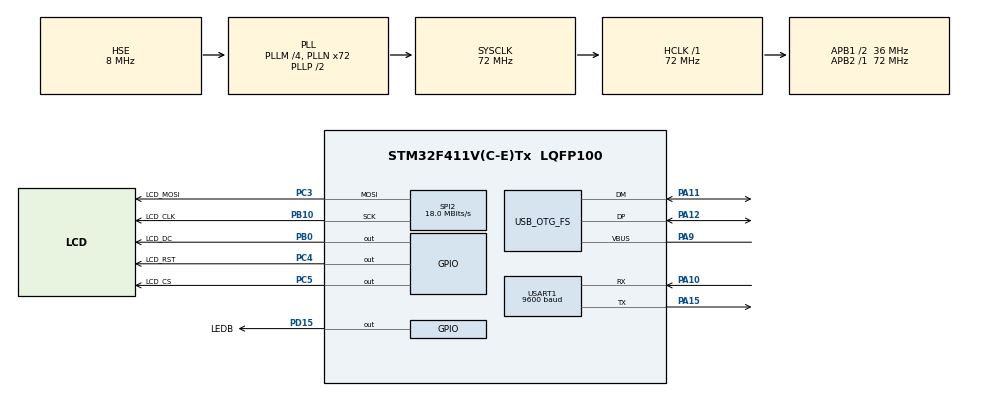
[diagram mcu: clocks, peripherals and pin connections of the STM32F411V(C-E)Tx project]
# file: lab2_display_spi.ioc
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Dma.Request0=USART1_RX
Dma.Request1=SPI2_TX
Dma.SPI2_TX.1.Direction=DMA_MEMORY_TO_PERIPH
Dma.SPI2_TX.1.FIFOMode=DMA_FIFOMODE_DISABLE
Dma.SPI2_TX.1.Instance=DMA1_Stream4
Dma.SPI2_TX.1.MemDataAlignment=DMA_MDATAALIGN_BYTE
Dma.SPI2_TX.1.MemInc=DMA_MINC_ENABLE
Dma.SPI2_TX.1.Mode=DMA_NORMAL
Dma.SPI2_TX.1.PeriphDataAlignment=DMA_PDATAALIGN_BYTE
Dma.SPI2_TX.1.PeriphInc=DMA_PINC_DISABLE
Dma.SPI2_TX.1.Priority=DMA_PRIORITY_LOW
Dma.USART1_RX.0.Direction=DMA_PERIPH_TO_MEMORY
Dma.USART1_RX.0.FIFOMode=DMA_FIFOMODE_DISABLE
Dma.USART1_RX.0.Instance=DMA2_Stream5
Dma.USART1_RX.0.MemDataAlignment=DMA_MDATAALIGN_BYTE
Dma.USART1_RX.0.MemInc=DMA_MINC_ENABLE
Dma.USART1_RX.0.Mode=DMA_CIRCULAR
Dma.USART1_RX.0.PeriphDataAlignment=DMA_PDATAALIGN_BYTE
Dma.USART1_RX.0.PeriphInc=DMA_PINC_DISABLE
Dma.USART1_RX.0.Priority=DMA_PRIORITY_LOW
Mcu.Family=STM32F4
Mcu.Name=STM32F411V(C-E)Tx
Mcu.Package=LQFP100
NVIC.DMA1_Stream4_IRQn=true\:0\:0\:false\:false\:true\:false\:true\:true
NVIC.DMA2_Stream5_IRQn=true\:0\:0\:false\:false\:true\:false\:true\:true
NVIC.OTG_FS_IRQn=true\:0\:0\:false\:false\:true\:false\:true\:true
NVIC.PriorityGroup=NVIC_PRIORITYGROUP_0
PA10.Mode=Asynchronous
PA10.Signal=USART1_RX
PA11.Mode=Device_Only
PA11.Signal=USB_OTG_FS_DM
PA12.Mode=Device_Only
PA12.Signal=USB_OTG_FS_DP
PA13.Mode=Serial_Wire
PA13.Signal=SYS_JTMS-SWDIO
PA14.Mode=Serial_Wire
PA14.Signal=SYS_JTCK-SWCLK
PA15.Mode=Asynchronous
PA15.Signal=USART1_TX
PA9.Mode=Activate_VBUS
PA9.Signal=USB_OTG_FS_VBUS
PB0.GPIO_Label=LCD_DC
PB0.GPIO_PuPd=GPIO_PULLUP
PB0.Signal=GPIO_Output
PB10.GPIO_Label=LCD_CLK
PB10.Mode=TX_Only_Simplex_Unidirect_Master
PB10.Signal=SPI2_SCK
PC14-OSC32_IN.Mode=LSE-External-Oscillator
PC14-OSC32_IN.Signal=RCC_OSC32_IN
PC15-OSC32_OUT.Mode=LSE-External-Oscillator
PC15-OSC32_OUT.Signal=RCC_OSC32_OUT
PC3.GPIO_Label=LCD_MOSI
PC3.Mode=TX_Only_Simplex_Unidirect_Master
PC3.Signal=SPI2_MOSI
PC4.GPIO_Label=LCD_RST
PC4.GPIO_PuPd=GPIO_PULLUP
PC4.Signal=GPIO_Output
PC5.GPIO_Label=LCD_CS
PC5.GPIO_PuPd=GPIO_PULLUP
PC5.Signal=GPIO_Output
PD15.GPIO_Label=LEDB
PD15.GPIO_PuPd=GPIO_PULLUP
PD15.Signal=GPIO_Output
PH0\ -\ OSC_IN.Mode=HSE-External-Oscillator
PH0\ -\ OSC_IN.Signal=RCC_OSC_IN
PH1\ -\ OSC_OUT.Mode=HSE-External-Oscillator
PH1\ -\ OSC_OUT.Signal=RCC_OSC_OUT
ProjectManager.HeapSize=0x0
ProjectManager.StackSize=0x400
ProjectManager.TargetToolchain=CMake
RCC.48MHZClocksFreq_Value=48000000
RCC.AHBFreq_Value=72000000
RCC.APB1CLKDivider=RCC_HCLK_DIV2
RCC.APB1Freq_Value=36000000
RCC.APB1TimFreq_Value=72000000
RCC.APB2Freq_Value=72000000
RCC.APB2TimFreq_Value=72000000
RCC.CortexFreq_Value=72000000
RCC.HCLKFreq_Value=72000000
RCC.HSE_VALUE=8000000
RCC.HSI_VALUE=16000000
RCC.PLLI2SM=5
RCC.PLLI2SN=200
RCC.PLLM=4
RCC.PLLN=72
RCC.PLLQ=3
RCC.SYSCLKFreq_VALUE=72000000
RCC.SYSCLKSource=RCC_SYSCLKSOURCE_PLLCLK
RCC.VCOOutputFreq_Value=144000000
SPI2.BaudRatePrescaler=SPI_BAUDRATEPRESCALER_2
SPI2.CalculateBaudRate=18.0 MBits/s
SPI2.Direction=SPI_DIRECTION_2LINES
SPI2.Mode=SPI_MODE_MASTER
SPI2.VirtualType=VM_MASTER
USART1.BaudRate=9600
USART1.Mode=MODE_TX_RX
USART1.VirtualMode=VM_ASYNC
USB_DEVICE.CLASS_NAME_FS=CDC
USB_DEVICE.VirtualMode=Cdc
USB_DEVICE.VirtualModeFS=Cdc_FS
USB_OTG_FS.VirtualMode=Device_Only
VP_USB_DEVICE_VS_USB_DEVICE_CDC_FS.Mode=CDC_FS
board=STM32F411E-DISCO

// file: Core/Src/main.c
/* USER CODE BEGIN Header */
/**
  ******************************************************************************
  * @file           : main.c
  * @brief          : Main program body
  ******************************************************************************
  * @attention
  *
  * Copyright (c) 2025 STMicroelectronics.
  * All rights reserved.
  *
  * This software is licensed under terms that can be found in the LICENSE file
  * in the root directory of this software component.
  * If no LICENSE file comes with this software, it is provided AS-IS.
  *
  ******************************************************************************
  */
/* USER CODE END Header */
#include "main.h"
#include "dma.h"
#include "spi.h"
#include "usart.h"
#include "usb_device.h"
#include "gpio.h"

/* USER CODE BEGIN Includes */
#include "app_main.h"

/* USER CODE END Includes */

void SystemClock_Config(void);

int main(void)
{

  /* MCU Configuration--------------------------------------------------------*/

  /* Reset of all peripherals, Initializes the Flash interface and the Systick. */
  HAL_Init();

  /* Configure the system clock */
  SystemClock_Config();

  /* Initialize all configured peripherals */
  MX_GPIO_Init();
  MX_DMA_Init();
  MX_USB_DEVICE_Init();
  MX_USART1_UART_Init();
  MX_SPI2_Init();
  /* USER CODE BEGIN 2 */

  app_main();

  /* USER CODE END 2 */

  /* Infinite loop */
  /* USER CODE BEGIN WHILE */

  // Should never be reached
  while (1)
  {
    /* USER CODE END WHILE */

  }
}

void SystemClock_Config(void)
{
  RCC_OscInitTypeDef RCC_OscInitStruct = {0};
  RCC_ClkInitTypeDef RCC_ClkInitStruct = {0};

  /** Configure the main internal regulator output voltage
  */
  __HAL_RCC_PWR_CLK_ENABLE();
  __HAL_PWR_VOLTAGESCALING_CONFIG(PWR_REGULATOR_VOLTAGE_SCALE1);

  /** Initializes the RCC Oscillators according to the specified parameters
  * in the RCC_OscInitTypeDef structure.
  */
  RCC_OscInitStruct.OscillatorType = RCC_OSCILLATORTYPE_HSE;
  RCC_OscInitStruct.HSEState = RCC_HSE_ON;
  RCC_OscInitStruct.PLL.PLLState = RCC_PLL_ON;
  RCC_OscInitStruct.PLL.PLLSource = RCC_PLLSOURCE_HSE;
  RCC_OscInitStruct.PLL.PLLM = 4;
  RCC_OscInitStruct.PLL.PLLN = 72;
  RCC_OscInitStruct.PLL.PLLP = RCC_PLLP_DIV2;
  RCC_OscInitStruct.PLL.PLLQ = 3;
  if (HAL_RCC_OscConfig(&RCC_OscInitStruct) != HAL_OK)
  {
    Error_Handler();
  }

  /** Initializes the CPU, AHB and APB buses clocks
  */
  RCC_ClkInitStruct.ClockType = RCC_CLOCKTYPE_HCLK|RCC_CLOCKTYPE_SYSCLK
                              |RCC_CLOCKTYPE_PCLK1|RCC_CLOCKTYPE_PCLK2;
  RCC_ClkInitStruct.SYSCLKSource = RCC_SYSCLKSOURCE_PLLCLK;
  RCC_ClkInitStruct.AHBCLKDivider = RCC_SYSCLK_DIV1;
  RCC_ClkInitStruct.APB1CLKDivider = RCC_HCLK_DIV2;
  RCC_ClkInitStruct.APB2CLKDivider = RCC_HCLK_DIV1;

  if (HAL_RCC_ClockConfig(&RCC_ClkInitStruct, FLASH_LATENCY_2) != HAL_OK)
  {
    Error_Handler();
  }
}

void Error_Handler(void)
{
  __disable_irq();
  while (1)
  {
  }
}
